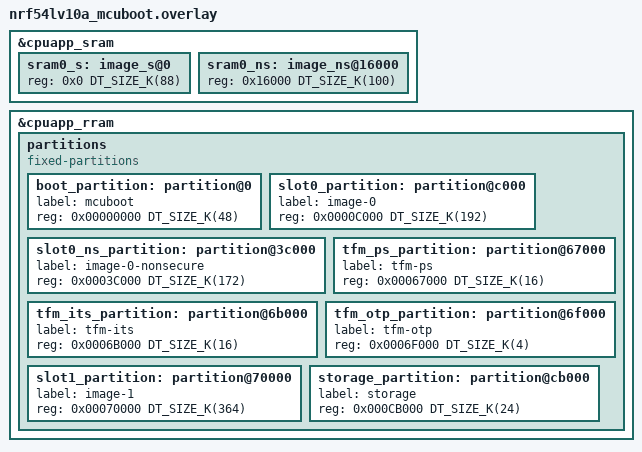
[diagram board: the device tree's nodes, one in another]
/*
 * Copyright (c) 2026 Nordic Semiconductor ASA
 *
 * SPDX-License-Identifier: LicenseRef-Nordic-5-Clause
 */

/*
 * TF-M partition layout with MCUboot for nRF54LV10A
 *
 * nRF54LV10A has 1012 kB of RRAM and 192 kB of SRAM.
 * TrustZone flash region alignment: 4 kB (MPC-based)
 * TrustZone RAM region alignment:   4 kB
 * RRAM erase-block-size:            4 kB
 *
 * This is a tighter layout than nRF54L15 due to less memory.
 * The secondary slot is sized to match the primary slot for
 * symmetric DFU (required by MCUboot default configuration).
 *
 * Suitable for: products with OTA firmware update on nRF54LV10A
 */

&cpuapp_sram {
	sram0_s: image_s@0 {
		#address-cells = <1>;
		#size-cells = <1>;
		reg = <0x0 DT_SIZE_K(88)>;
		ranges = <0x0 0x0 DT_SIZE_K(88)>;
	};

	/* 100 kB NS — 4 kB unused at top */
	sram0_ns: image_ns@16000 {
		#address-cells = <1>;
		#size-cells = <1>;
		reg = <0x16000 DT_SIZE_K(100)>;
		ranges = <0x0 0x16000 DT_SIZE_K(100)>;
	};
};

&cpuapp_rram {
	partitions {
		compatible = "fixed-partitions";
		#address-cells = <1>;
		#size-cells = <1>;

		/*
		 * Flash layout (all addresses 4 kB aligned):
		 *
		 * 0x00000000  MCUboot bootloader       (48 kB)
		 * 0x0000C000  Primary slot:
		 *   0x0000C000  TF-M secure image      (192 kB)
		 *   0x0003C000  Non-secure application  (172 kB)
		 * 0x00067000  TF-M PS                   (16 kB)
		 * 0x0006B000  TF-M ITS                  (16 kB)
		 * 0x0006F000  TF-M OTP / NV counters     (4 kB)
		 * 0x00070000  Secondary slot           (364 kB)
		 * 0x000CB000  Non-secure storage        (24 kB)
		 *
		 * Primary = 192 + 172 = 364 kB = Secondary
		 * Total: 48 + 364 + 16 + 16 + 4 + 364 + 24 = 836 kB
		 * (within 1012 kB RRAM, ~176 kB margin for FLPR)
		 */

		boot_partition: partition@0 {
			label = "mcuboot";
			reg = <0x00000000 DT_SIZE_K(48)>;
		};

		slot0_partition: partition@c000 {
			label = "image-0";
			reg = <0x0000C000 DT_SIZE_K(192)>;
		};

		slot0_ns_partition: partition@3c000 {
			label = "image-0-nonsecure";
			reg = <0x0003C000 DT_SIZE_K(172)>;
		};

		tfm_ps_partition: partition@67000 {
			label = "tfm-ps";
			reg = <0x00067000 DT_SIZE_K(16)>;
		};

		tfm_its_partition: partition@6b000 {
			label = "tfm-its";
			reg = <0x0006B000 DT_SIZE_K(16)>;
		};

		tfm_otp_partition: partition@6f000 {
			label = "tfm-otp";
			reg = <0x0006F000 DT_SIZE_K(4)>;
		};

		slot1_partition: partition@70000 {
			label = "image-1";
			reg = <0x00070000 DT_SIZE_K(364)>;
		};

		storage_partition: partition@cb000 {
			label = "storage";
			reg = <0x000CB000 DT_SIZE_K(24)>;
		};
	};
};
